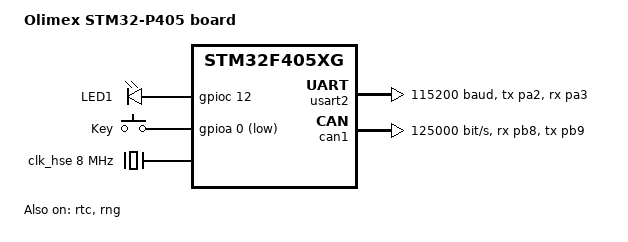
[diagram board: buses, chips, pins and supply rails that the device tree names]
/*
 * Copyright (c) 2017, Erwin Rol <erwin@erwinrol.com>
 *
 * SPDX-License-Identifier: Apache-2.0
 */

/dts-v1/;
#include <st/f4/stm32f405Xg.dtsi>
#include <st/f4/stm32f405rgtx-pinctrl.dtsi>
#include <zephyr/dt-bindings/input/input-event-codes.h>

/ {
	model = "Olimex STM32-P405 board";
	compatible = "olimex,stm32-p405";

	chosen {
		zephyr,console = &usart2;
		zephyr,shell-uart = &usart2;
		zephyr,sram = &sram0;
		zephyr,flash = &flash0;
		zephyr,ccm = &ccm0;
		zephyr,canbus = &can1;
	};

	leds {
		compatible = "gpio-leds";
		green_led_1: led_1 {
			gpios = <&gpioc 12 GPIO_ACTIVE_HIGH>;
			label = "LED1";
		};
	};

	gpio_keys {
		compatible = "gpio-keys";
		user_button: button {
			label = "Key";
			gpios = <&gpioa 0 GPIO_ACTIVE_LOW>;
			zephyr,code = <INPUT_KEY_0>;
		};
	};

	aliases {
		led0 = &green_led_1;
		sw0 = &user_button;
	};
};

&clk_lsi {
	status = "okay";
};

&clk_hse {
	clock-frequency = <DT_FREQ_M(8)>;
	status = "okay";
};

&pll {
	div-m = <4>;
	mul-n = <168>;
	div-p = <2>;
	div-q = <7>;
	clocks = <&clk_hse>;
	status = "okay";
};

&rcc {
	clocks = <&pll>;
	clock-frequency = <DT_FREQ_M(168)>;
	ahb-prescaler = <1>;
	apb1-prescaler = <4>;
	apb2-prescaler = <2>;
};

&usart2 {
	pinctrl-0 = <&usart2_tx_pa2 &usart2_rx_pa3>;
	pinctrl-names = "default";
	current-speed = <115200>;
	status = "okay";
};

&rtc {
	clocks = <&rcc STM32_CLOCK_BUS_APB1 0x10000000>,
		 <&rcc STM32_SRC_LSI RTC_SEL(2)>;
	status = "okay";
};

&can1 {
	pinctrl-0 = <&can1_rx_pb8 &can1_tx_pb9>;
	pinctrl-names = "default";
	bus-speed = <125000>;
	status = "okay";

	can-transceiver {
		max-bitrate = <1000000>;
	};
};

&rng {
	status = "okay";
};
